# ESW3120 register map
Vendor: Shanghai Eastsoft Microelectronics Co.,Ltd.; Series: ARMCM3; File version: 1.2
ARM 32-bit Cortex-M3 Microcontroller based device, CPU clock up to 48MHz, etc.
CPU: CM3 r2p1, little endian, MPU, no FPU, 4 interrupt priority bits
Registers are 32-bit, read-write, reset 0x0 unless marked. A register's access mark holds for its fields unless they carry their own. Offsets are from the block's base; lines under a group give offsets from that group; [hi:lo] are bit positions; {n}, {i} and the like mark numbered series; 'fields as' and 'values as' point back to an identical list; <NAME> marks a mode.

## Memory map
0x40000000 GP16C4T0 size 0x2000
0x40000400 GP16C4T1 size 0x2000
0x40000800 AD16C4T0 size 0x2000
0x40000C00 AD16C4T1 size 0x2000
0x40001000 BS16T0 size 0x2000
0x40001400 BS16T1 size 0x2000
0x40004000 UART0 size 0x2000
0x40004400 UART1 size 0x2000
0x40004800 UART2 size 0x2000
0x40006000 SPI0 size 0x2000
0x40006400 SPI1 size 0x2000
0x40008000 I2C0 size 0x2000
0x40008400 I2C1 size 0x2000
0x40008800 ADPCM size 0x2000
0x40008C00 TK size 0x2000
0x40009000 PDM2PCM size 0x2000
0x40009800 ECC size 0x2000
0x4000C000 DMA size 0x2000
0x4000E000 QSPI size 0x2000
0x4000F000 KSCAN size 0x2000
0x4000F400 QDEC size 0x2000
0x40040000 LP16T size 0x2000
0x40042000 ADC size 0x2000
0x40046000 WWDT size 0x2000
0x40048000 IWDT size 0x2000
0x40048400 RTC size 0x2000
0x40049000 BKPC size 0x2000
0x4004A000 DBGC size 0x2000
0x40080000 SYSCFG size 0x2000
0x40080400 CMU size 0x2000
0x40080800 RMU size 0x2000
0x40080C00 PMU size 0x2000
0x40081000 MSC size 0x2000
0x40083C00 CFG size 0x2000
0x40084000 GPIOA size 0x2000
0x40084040 GPIOB size 0x2000
0x40084300 GPIOEXTI size 0x2000
0x40085000 CRC size 0x2000
0x40085400 CALC size 0x2000
0x40085800 CRYPT size 0x2000
0x40085C00 TRNG size 0x2000
0x40086000 PIS size 0x2000
0x40086800 HASH size 0x2000
0x400E0400 AFE size 0x2000

## WWDT
Base 0x40046000
0x00 LOAD write reset 0x20000
0x04 VALUE read reset 0x3FFFFFFF
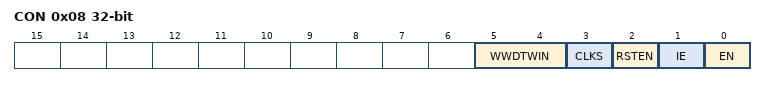
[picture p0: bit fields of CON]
0x08 CON write1
  [5:4] WWDTWIN rw, [3] CLKS rw, [2] RSTEN rw, [1] IE rw, [0] EN
0x0C INTCLR write
0x10 RIS read
  [0] WWDTIF
0x100 LOCK read reset 0x1
  [0] LOCK

## UART0
Base 0x40004000
Same registers: UART1 0x40004400, UART2 0x40004800
0x00 RXBUF read
  [8:0] RXBUF
0x04 TXBUF
  [8:0] TXBUF
0x08 BRR
  [15:0] BRR
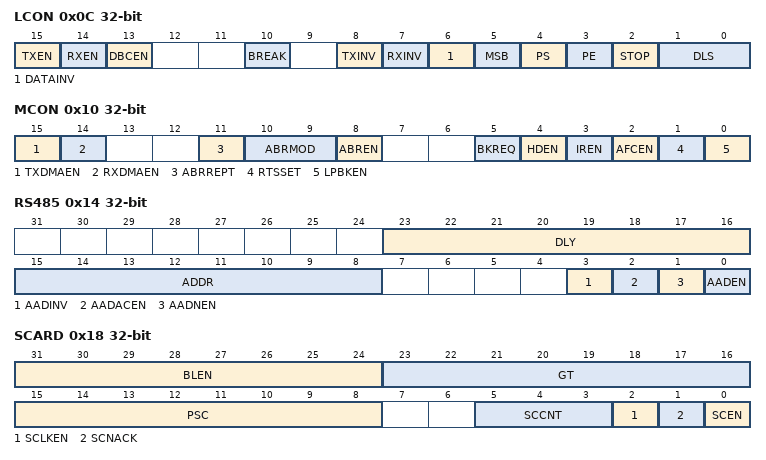
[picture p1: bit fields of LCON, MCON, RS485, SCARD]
0x0C LCON
  [15] TXEN, [14] RXEN, [13] DBCEN, [10] BREAK, [8] TXINV, [7] RXINV, [6] DATAINV, [5] MSB, [4] PS, [3] PE, [2] STOP, [1:0] DLS
0x10 MCON
  [15] TXDMAEN, [14] RXDMAEN, [11] ABRREPT, [10:9] ABRMOD, [8] ABREN, [5] BKREQ write, [4] HDEN, [3] IREN, [2] AFCEN, [1] RTSSET, [0] LPBKEN
0x14 RS485
  [23:16] DLY, [15:8] ADDR, [3] AADINV, [2] AADACEN, [1] AADNEN, [0] AADEN
0x18 SCARD
  [31:24] BLEN, [23:16] GT, [15:8] PSC, [5:3] SCCNT, [2] SCLKEN, [1] SCNACK, [0] SCEN
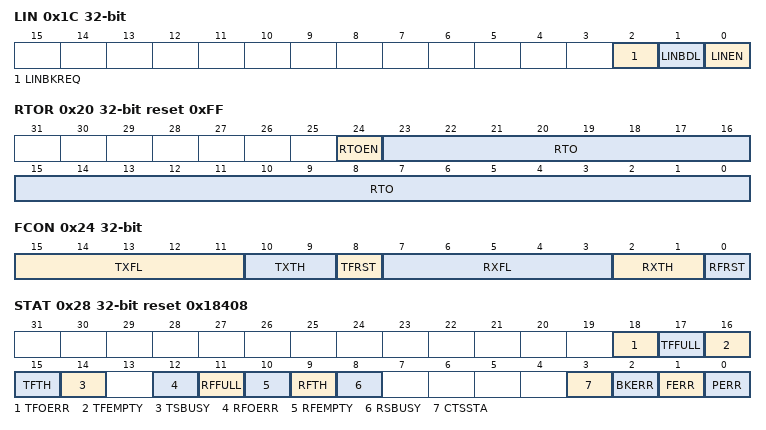
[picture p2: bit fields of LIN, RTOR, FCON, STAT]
0x1C LIN
  [2] LINBKREQ write1, [1] LINBDL, [0] LINEN
0x20 RTOR reset 0xFF
  [24] RTOEN, [23:0] RTO
0x24 FCON write1
  [15:11] TXFL read, [10:9] TXTH rw, [8] TFRST, [7:3] RXFL read, [2:1] RXTH rw, [0] RFRST
0x28 STAT read reset 0x18408
  [18] TFOERR, [17] TFFULL, [16] TFEMPTY, [15] TFTH, [14] TSBUSY, [12] RFOERR, [11] RFFULL, [10] RFEMPTY, [9] RFTH, [8] RSBUSY, [3] CTSSTA, [2] BKERR, [1] FERR, [0] PERR
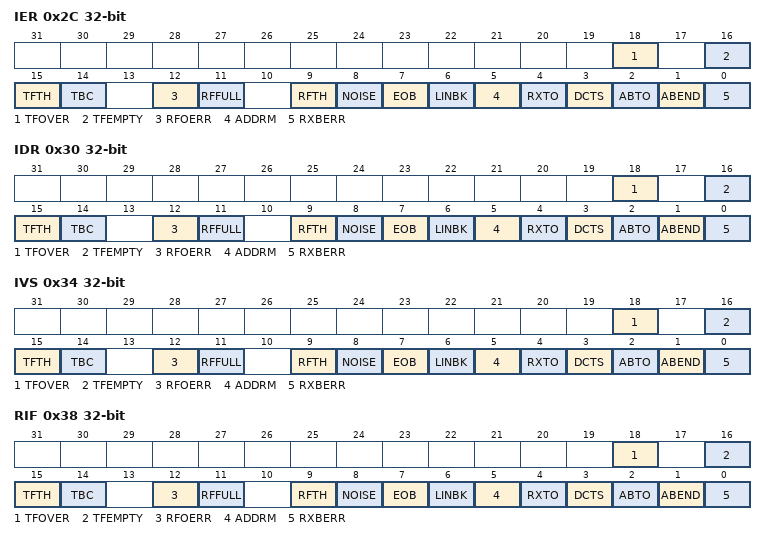
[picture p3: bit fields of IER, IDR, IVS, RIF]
0x2C IER write1
  [18] TFOVER, [16] TFEMPTY, [15] TFTH, [14] TBC, [12] RFOERR, [11] RFFULL, [9] RFTH, [8] NOISE, [7] EOB, [6] LINBK, [5] ADDRM, [4] RXTO, [3] DCTS, [2] ABTO, [1] ABEND, [0] RXBERR
0x30 IDR write1
  fields as IER
0x34 IVS read
  fields as IER
0x38 RIF read
  fields as IER
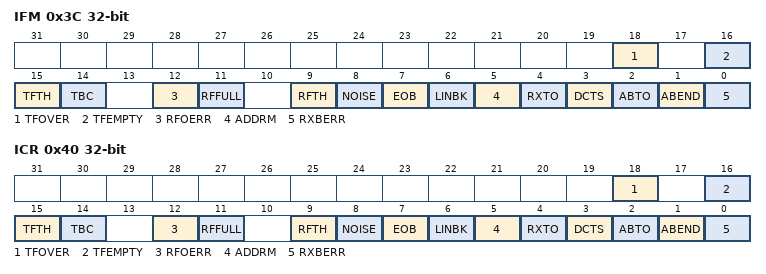
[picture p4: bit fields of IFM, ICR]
0x3C IFM read
  fields as IER
0x40 ICR clear-write1
  fields as IER

## Licence text in the file
ARM Limited (ARM) is supplying this software for use with Cortex-M processor based microcontroller, but can be equally used for other suitable processor architectures. This file can be freely distributed. Modifications to this file shall be clearly marked. . THIS SOFTWARE IS PROVIDED "AS IS". NO WARRANTIES, WHETHER EXPRESS, IMPLIED. OR STATUTORY, INCLUDING, BUT NOT LIMITED TO, IMPLIED WARRANTIES OF. MERCHANTABILITY AND FITNESS FOR A PARTICULAR PURPOSE APPLY TO THIS SOFTWARE. ARM SHALL NOT, IN ANY CIRCUMSTANCES, BE LIABLE FOR SPECIAL, INCIDENTAL, OR. CONSEQUENTIAL DAMAGES, FOR ANY REASON WHATSOEVER.

## Notices in the file
Copyright (C) 2016 ARM Limited. All rights reserved.
